# ESP32-S2 register map
Vendor: ESPRESSIF SYSTEMS (SHANGHAI) CO., LTD.; Series: ESP32 S-Series; File version: 20
CPU: Xtensa LX7 r0p0, little endian, no MPU, no FPU, 0 interrupt priority bits
Address unit: 32 bits
Registers are 32-bit, read-write, reset 0x0 unless marked. A register's access mark holds for its fields unless they carry their own. Offsets are from the block's base; [hi:lo] are bit positions; {n}, {i} and the like mark numbered series.

## SYSTEM — System Configuration Registers
Base 0x3F4C0000
0x00 ROM_CTRL_0 reset 0x3 — System ROM configuration register 0
  [1:0] ROM_FO — This field is used to force on clock gate of internal ROM.
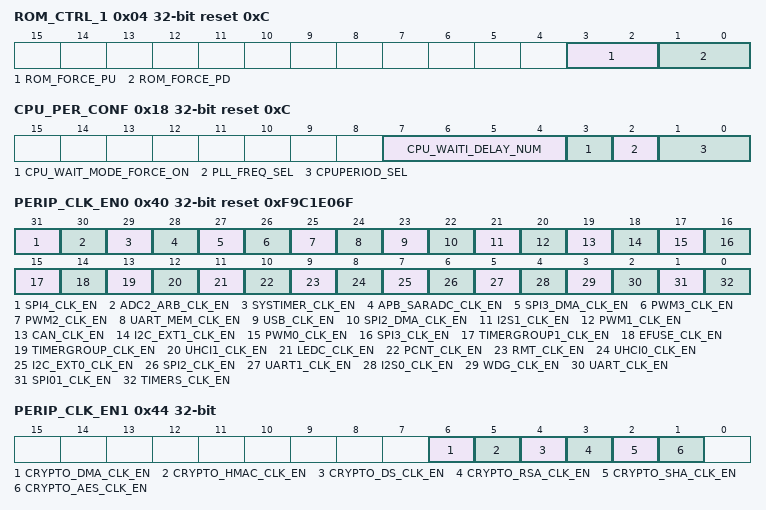
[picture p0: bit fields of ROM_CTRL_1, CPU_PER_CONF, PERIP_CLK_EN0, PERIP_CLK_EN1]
0x04 ROM_CTRL_1 reset 0xC — System ROM configuration register 1
  [3:2] ROM_FORCE_PU — This field is used to power up internal ROM.
  [1:0] ROM_FORCE_PD — This field is used to power down internal ROM.
0x08 SRAM_CTRL_0 reset 0x3FFFFF — System SRAM configuration register 0
  [21:0] SRAM_FO — This field is used to force on clock gate of internal SRAM.
0x0C SRAM_CTRL_1 — System SRAM configuration register 1
  [21:0] SRAM_FORCE_PD — This field is used to power down internal SRAM.
0x10 CPU_PERI_CLK_EN — CPU peripheral clock enable register
  [7] CLK_EN_DEDICATED_GPIO — Set this bit to enable clock of DEDICATED GPIO module.
0x14 CPU_PERI_RST_EN reset 0x80 — CPU peripheral reset register
  [7] RST_EN_DEDICATED_GPIO — Set this bit to reset DEDICATED GPIO module.
0x18 CPU_PER_CONF reset 0xC — CPU peripheral clock configuration register
  [7:4] CPU_WAITI_DELAY_NUM — Sets the number of delay cycles to enter CPU wait mode after a WAITI instruction.
  [3] CPU_WAIT_MODE_FORCE_ON — Set this bit to force on CPU wait mode. In this mode, the clock gate of CPU is turned off until any interrupts happen. This mode could also be force on via WAITI instruction.
  [2] PLL_FREQ_SEL — This field is used to select the PLL clock frequency based on CPU period.
  [1:0] CPUPERIOD_SEL — This field is used to select the clock frequency of CPU or CPU period.
{0x1C+4i} JTAG_CTRL_{i} wo (i=0..6) — JTAG configuration register {i}
  [31:0] CANCEL_EFUSE_DISABLE_JTAG_TEMPORARY_{i} — Stores the {32i} to {32i+31} bits of the 256 bits register used to cancel the temporary disable of eFuse to JTAG.
0x38 JTAG_CTRL_7 wo — JTAG configuration register 7
  [31:0] CANCEL_EFUSE_DISABLE_JTAG_TEMPORARY_7 — Stores the 0 to 224 bits of the 255 bits register used to cancel the temporary disable of eFuse to JTAG.
0x3C MEM_PD_MASK reset 0x1 — Memory power-related controlling register (under low-sleep)
  [0] LSLP_MEM_PD_MASK — Set this bit to allow the memory to work as usual when the chip enters the light-sleep state.
0x40 PERIP_CLK_EN0 reset 0xF9C1E06F — System peripheral clock (for hardware accelerators) enable register
  [31] SPI4_CLK_EN — Set this bit to enable clock of SPI4.
  [30] ADC2_ARB_CLK_EN — Set this bit to enable clock of aribiter of ADC2.
  [29] SYSTIMER_CLK_EN — Set this bit to enable clock of system timer.
  [28] APB_SARADC_CLK_EN — Set this bit to enable clock of SAR ADC.
  [27] SPI3_DMA_CLK_EN — Set this bit to enable clock of SPI3 DMA.
  [26] PWM3_CLK_EN — Set this bit to enable clock of PWM3.
  [25] PWM2_CLK_EN — Set this bit to enable clock of PWM2.
  [24] UART_MEM_CLK_EN — Set this bit to enable clock of UART memory.
  [23] USB_CLK_EN — Set this bit to enable clock of USB.
  [22] SPI2_DMA_CLK_EN — Set this bit to enable clock of SPI2 DMA.
  [21] I2S1_CLK_EN — Set this bit to enable clock of I2S1.
  [20] PWM1_CLK_EN — Set this bit to enable clock of PWM1.
  [19] CAN_CLK_EN — Set this bit to enable clock of CAN.
  [18] I2C_EXT1_CLK_EN — Set this bit to enable clock of I2C EXT1.
  [17] PWM0_CLK_EN — Set this bit to enable clock of PWM0.
  [16] SPI3_CLK_EN — Set this bit to enable clock of SPI3.
  [15] TIMERGROUP1_CLK_EN — Set this bit to enable clock of timer group1.
  [14] EFUSE_CLK_EN — Set this bit to enable clock of eFuse.
  [13] TIMERGROUP_CLK_EN — Set this bit to enable clock of timer group0.
  [12] UHCI1_CLK_EN — Set this bit to enable clock of UHCI1.
  [11] LEDC_CLK_EN — Set this bit to enable clock of LED PWM.
  [10] PCNT_CLK_EN — Set this bit to enable clock of pulse count.
  [9] RMT_CLK_EN — Set this bit to enable clock of remote controller.
  [8] UHCI0_CLK_EN — Set this bit to enable clock of UHCI0.
  [7] I2C_EXT0_CLK_EN — Set this bit to enable clock of I2C EXT0.
  [6] SPI2_CLK_EN — Set this bit to enable clock of SPI2.
  [5] UART1_CLK_EN — Set this bit to enable clock of UART1.
  [4] I2S0_CLK_EN — Set this bit to enable clock of I2S0.
  [3] WDG_CLK_EN — Set this bit to enable clock of WDG.
  [2] UART_CLK_EN — Set this bit to enable clock of UART0.
  [1] SPI01_CLK_EN — Set this bit to enable clock of SPI0 and SPI1.
  [0] TIMERS_CLK_EN — Set this bit to enable clock of timers.
0x44 PERIP_CLK_EN1 — System peripheral clock (for hardware accelerators) enable register 1
  [6] CRYPTO_DMA_CLK_EN — Set this bit to enable clock of cryptography DMA.
  [5] CRYPTO_HMAC_CLK_EN — Set this bit to enable clock of cryptography HMAC.
  [4] CRYPTO_DS_CLK_EN — Set this bit to enable clock of cryptography Digital Signature.
  [3] CRYPTO_RSA_CLK_EN — Set this bit to enable clock of cryptography RSA.
  [2] CRYPTO_SHA_CLK_EN — Set this bit to enable clock of cryptography SHA.
  [1] CRYPTO_AES_CLK_EN — Set this bit to enable clock of cryptography AES.
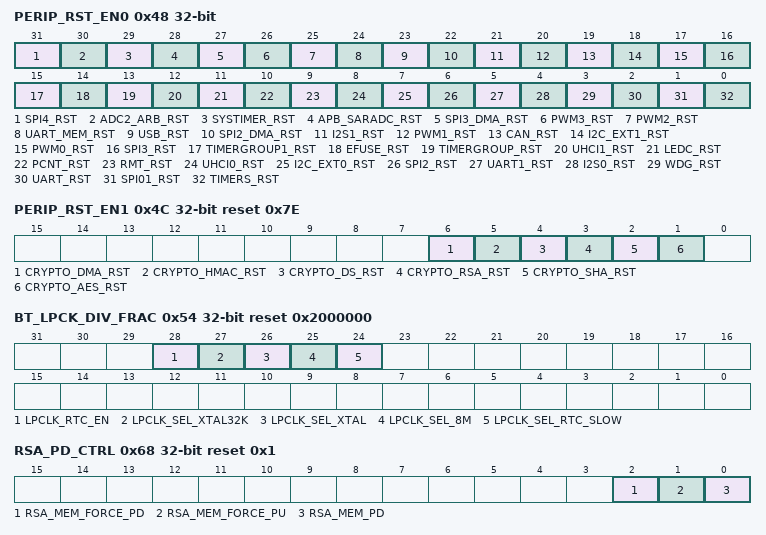
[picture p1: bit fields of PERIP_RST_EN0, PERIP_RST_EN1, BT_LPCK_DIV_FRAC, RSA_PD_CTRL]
0x48 PERIP_RST_EN0 — System peripheral (hardware accelerators) reset register 0
  [31] SPI4_RST — Set this bit to reset SPI4.
  [30] ADC2_ARB_RST — Set this bit to reset aribiter of ADC2.
  [29] SYSTIMER_RST — Set this bit to reset system timer.
  [28] APB_SARADC_RST — Set this bit to reset SAR ADC.
  [27] SPI3_DMA_RST — Set this bit to reset SPI3 DMA.
  [26] PWM3_RST — Set this bit to reset PWM3.
  [25] PWM2_RST — Set this bit to reset PWM2.
  [24] UART_MEM_RST — Set this bit to reset UART memory.
  [23] USB_RST — Set this bit to reset USB.
  [22] SPI2_DMA_RST — Set this bit to reset SPI2 DMA.
  [21] I2S1_RST — Set this bit to reset I2S1.
  [20] PWM1_RST — Set this bit to reset PWM1.
  [19] CAN_RST — Set this bit to reset CAN.
  [18] I2C_EXT1_RST — Set this bit to reset I2C EXT1.
  [17] PWM0_RST — Set this bit to reset PWM0.
  [16] SPI3_RST — Set this bit to reset SPI3.
  [15] TIMERGROUP1_RST — Set this bit to reset timer group1.
  [14] EFUSE_RST — Set this bit to reset eFuse.
  [13] TIMERGROUP_RST — Set this bit to reset timer group0.
  [12] UHCI1_RST — Set this bit to reset UHCI1.
  [11] LEDC_RST — Set this bit to reset LED PWM.
  [10] PCNT_RST — Set this bit to reset pulse count.
  [9] RMT_RST — Set this bit to reset remote controller.
  [8] UHCI0_RST — Set this bit to reset UHCI0.
  [7] I2C_EXT0_RST — Set this bit to reset I2C EXT0.
  [6] SPI2_RST — Set this bit to reset SPI2.
  [5] UART1_RST — Set this bit to reset UART1.
  [4] I2S0_RST — Set this bit to reset I2S0.
  [3] WDG_RST — Set this bit to reset WDG.
  [2] UART_RST — Set this bit to reset UART0.
  [1] SPI01_RST — Set this bit to reset SPI0 and SPI1.
  [0] TIMERS_RST — Set this bit to reset timers.
0x4C PERIP_RST_EN1 reset 0x7E — System peripheral (hardware accelerators) reset register 1
  [6] CRYPTO_DMA_RST — Set this bit to reset cryptography DMA.
  [5] CRYPTO_HMAC_RST — Set this bit to reset cryptography HMAC.
  [4] CRYPTO_DS_RST — Set this bit to reset cryptography digital signature.
  [3] CRYPTO_RSA_RST — Set this bit to reset cryptography RSA.
  [2] CRYPTO_SHA_RST — Set this bit to reset cryptography SHA.
  [1] CRYPTO_AES_RST — Set this bit to reset cryptography AES.
0x50 LPCK_DIV_INT reset 0xFF — Low power clock divider integer register
  [11:0] LPCK_DIV_NUM — This field is used to set the integer number of the divider value.
0x54 BT_LPCK_DIV_FRAC reset 0x2000000 — Divider fraction configuration register for low-power clock
  [28] LPCLK_RTC_EN — Set this bit to enable the RTC low power clock.
  [27] LPCLK_SEL_XTAL32K — Set this bit to select xtal32k clock as the low power clock.
  [26] LPCLK_SEL_XTAL — Set this bit to select xtal clock as the low power clock.
  [25] LPCLK_SEL_8M — Set this bit to select 8m clock as the low power clock.
  [24] LPCLK_SEL_RTC_SLOW — Set this bit to select RTC slow clock as the low power clock.
{0x58+4i} CPU_INTR_FROM_CPU_{i} (i=0..3) — CPU interrupt controlling register {i}
  [0] CPU_INTR_FROM_CPU_{i} — Set this bit to generate CPU interrupt {i}. This bit needs to be reset by software in the ISR process.
0x68 RSA_PD_CTRL reset 0x1 — RSA memory remapping register
  [2] RSA_MEM_FORCE_PD — Set this bit to force power down RSA memory. This bit has the highest priority.
  [1] RSA_MEM_FORCE_PU — Set this bit to force power up RSA memory. This bit has the second highest priority.
  [0] RSA_MEM_PD — Set this bit to power down RSA memory. This bit has the lowest priority. When Digital Signature occupies the RSA, this bit is invalid.
0x6C BUSTOEXTMEM_ENA reset 0x1 — EDMA enable register
  [0] BUSTOEXTMEM_ENA — Set this bit to enable bus to EDMA.
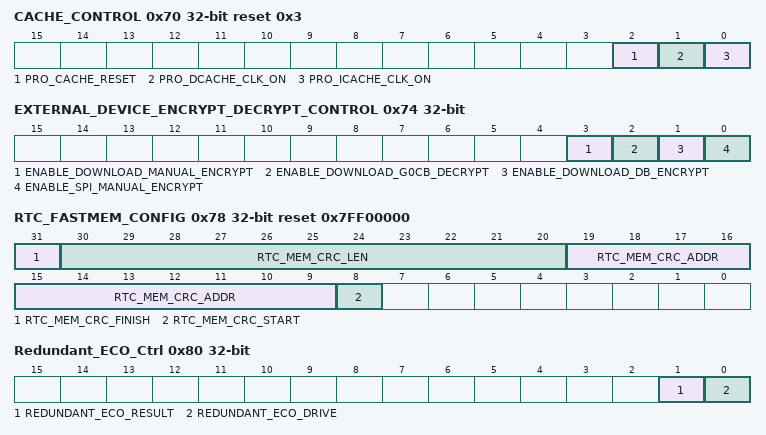
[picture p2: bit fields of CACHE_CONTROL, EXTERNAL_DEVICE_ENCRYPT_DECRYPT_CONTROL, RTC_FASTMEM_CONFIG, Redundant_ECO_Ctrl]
0x70 CACHE_CONTROL reset 0x3
  [2] PRO_CACHE_RESET — Set this bit to reset cache.
  [1] PRO_DCACHE_CLK_ON — Set this bit to enable clock of d-cache.
  [0] PRO_ICACHE_CLK_ON — Set this bit to enable clock of i-cache.
0x74 EXTERNAL_DEVICE_ENCRYPT_DECRYPT_CONTROL — External memory encrypt and decrypt controlling register
  [3] ENABLE_DOWNLOAD_MANUAL_ENCRYPT — Set this bit to enable Manual Encryption under Download Boot mode.
  [2] ENABLE_DOWNLOAD_G0CB_DECRYPT — Set this bit to enable Auto Decryption under Download Boot mode.
  [1] ENABLE_DOWNLOAD_DB_ENCRYPT — Set this bit to enable Auto Encryption under Download Boot mode.
  [0] ENABLE_SPI_MANUAL_ENCRYPT — Set this bit to enable Manual Encryption under SPI Boot mode.
0x78 RTC_FASTMEM_CONFIG access per field reset 0x7FF00000 — RTC fast memory configuration register
  [31] RTC_MEM_CRC_FINISH ro — This bit stores the status of RTC memory CRC. High level means finished while low level means not finished.
  [30:20] RTC_MEM_CRC_LEN rw — This field is used to set length of RTC memory for CRC based on start address.
  [19:9] RTC_MEM_CRC_ADDR rw — This field is used to set address of RTC memory for CRC.
  [8] RTC_MEM_CRC_START rw — Set this bit to start the CRC of RTC memory.
0x7C RTC_FASTMEM_CRC ro — RTC fast memory CRC controlling register
  [31:0] RTC_MEM_CRC_RES — This field stores the CRC result of RTC memory.
0x80 Redundant_ECO_Ctrl access per field — Redundant ECO control register
  [1] REDUNDANT_ECO_RESULT ro — The redundant ECO result bit to avoid optimization in circuits.
  [0] REDUNDANT_ECO_DRIVE rw — The redundant ECO drive bit to avoid optimization in circuits.
0x84 CLOCK_GATE reset 0x1 — Clock gate control register
  [0] CLK_EN — Set this bit to enable clock of this module.
0x88 SRAM_CTRL_2 reset 0x3FFFFF — System SRAM configuration register 2
  [21:0] SRAM_FORCE_PU — This field is used to power up internal SRAM.
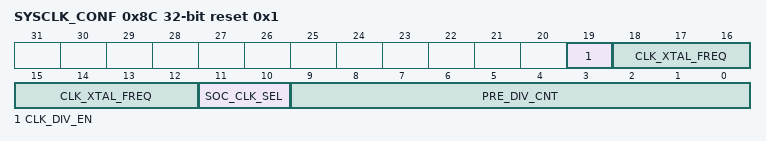
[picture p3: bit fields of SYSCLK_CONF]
0x8C SYSCLK_CONF access per field reset 0x1 — SoC clock configuration register
  [19] CLK_DIV_EN ro — Not used, extends from ESP32.
  [18:12] CLK_XTAL_FREQ ro — This field is used to read XTAL frequency in MHz.
  [11:10] SOC_CLK_SEL rw — This field is used to select SOC clock.
  [9:0] PRE_DIV_CNT rw — This field is used to set the count of prescaler of XTAL\_CLK.
0xFFC DATE reset 0x1908020 — Version control register
  [27:0] DATE — Version control register.
